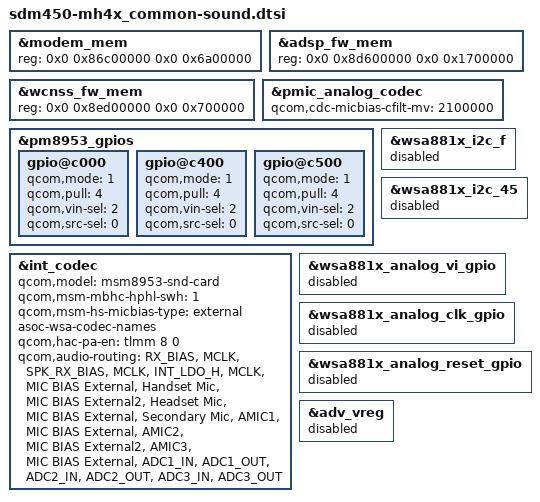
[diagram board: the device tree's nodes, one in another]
/*
 * Copyright (c) 2018, The Linux Foundation. All rights reserved.
 *
 * This program is free software; you can redistribute it and/or modify
 * it under the terms of the GNU General Public License version 2 and
 * only version 2 as published by the Free Software Foundation.
 *
 * This program is distributed in the hope that it will be useful,
 * but WITHOUT ANY WARRANTY; without even the implied warranty of
 * MERCHANTABILITY or FITNESS FOR A PARTICULAR PURPOSE.  See the
 * GNU General Public License for more details.
 */

#include "../../../qcom/msm8953-audio.dtsi"

&modem_mem {
	reg = <0x0 0x86c00000 0x0 0x6a00000>;
};

&adsp_fw_mem {
	reg = <0x0 0x8d600000 0x0 0x1700000>;
};

&wcnss_fw_mem {
	reg = <0x0 0x8ed00000 0x0 0x700000>;
};

&pmic_analog_codec {
    status = "okay";
    qcom,cdc-micbias-cfilt-mv = <2100000>;
};

&pm8953_gpios {
    gpio@c000 {
        qcom,mode = <1>;
        qcom,pull = <4>;
        qcom,vin-sel = <2>;
        qcom,src-sel = <0>;
        status = "okay";
    };
    gpio@c400 {
        qcom,mode = <1>;
        qcom,pull = <4>;
        qcom,vin-sel = <2>;
        qcom,src-sel = <0>;
        status = "okay";
    };
    gpio@c500 {
        qcom,mode = <1>;
        qcom,pull = <4>;
        qcom,vin-sel = <2>;
        qcom,src-sel = <0>;
        status = "okay";
    };
};

&int_codec {
    status = "okay";
    qcom,model = "msm8953-snd-card";
    qcom,msm-mbhc-hphl-swh = <1>;
    qcom,msm-hs-micbias-type = "external";
    asoc-wsa-codec-names;
    qcom,hac-pa-en = <&tlmm 8 0>;

    qcom,audio-routing =
        "RX_BIAS", "MCLK",
        "SPK_RX_BIAS", "MCLK",
        "INT_LDO_H", "MCLK",
        "MIC BIAS External", "Handset Mic",
        "MIC BIAS External2", "Headset Mic",
        "MIC BIAS External", "Secondary Mic",
        "AMIC1", "MIC BIAS External",
        "AMIC2", "MIC BIAS External2",
        "AMIC3", "MIC BIAS External",
        "ADC1_IN", "ADC1_OUT",
        "ADC2_IN", "ADC2_OUT",
        "ADC3_IN", "ADC3_OUT";
};

&wsa881x_i2c_f {
	status = "disabled";
};

&wsa881x_i2c_45 {
	status = "disabled";
};

&wsa881x_analog_vi_gpio {
	status = "disabled";
};

&wsa881x_analog_clk_gpio {
	status = "disabled";
};

&wsa881x_analog_reset_gpio {
	status = "disabled";
};

&adv_vreg {
    status = "disabled";
};

